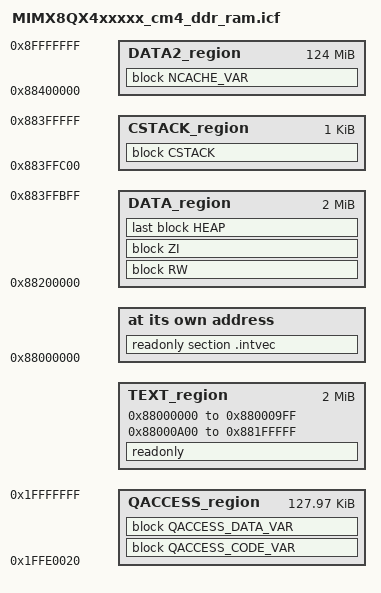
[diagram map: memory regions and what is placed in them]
/*
** ###################################################################
**     Processor:           MIMX8QX4AVLFZ
**     Compiler:            IAR ANSI C/C++ Compiler for ARM
**     Reference manual:    IMX8DQXPRM, Rev. E, 6/2019
**     Version:             rev. 3.0, 2018-08-22
**     Build:               b191127
**
**     Abstract:
**         Linker file for the IAR ANSI C/C++ Compiler for ARM
**
**     Copyright 2016 Freescale Semiconductor, Inc.
**     Copyright 2016-2019 NXP
**     All rights reserved.
**
**     SPDX-License-Identifier: BSD-3-Clause
**
**     http:                 www.nxp.com
**     mail:                 support@nxp.com
**
** ###################################################################
*/

/* DDR Memory region [0x88000000-0x8FFFFFFF] 128MB is allocated for CM4 */

define symbol m_interrupts_start       = 0x88000000;
define symbol m_interrupts_end         = 0x880009FF;

define symbol m_text_start             = 0x88000A00;
define symbol m_text_end               = 0x881FFFFF;

define symbol m_data_start             = 0x88200000;
define symbol m_data_end               = 0x883FFFFF;

define symbol m_data2_start            = 0x88400000;
define symbol m_data2_end              = 0x8FFFFFFF;

/* M4 always start up from TCM. The SCU will copy the first 32 bytes of the binary to TCM
if the start address is not TCM. The TCM region [0x1FFE0000-0x1FFE001F] is reserved for this purpose. */
define symbol m_tcml_start             = 0x1FFE0020;
define symbol m_tcml_end               = 0x1FFFFFFF;

define symbol m_tcmu_start             = 0x20000000;
define symbol m_tcmu_end               = 0x2001FFFF;

/* Sizes */
if (isdefinedsymbol(__stack_size__)) {
  define symbol __size_cstack__        = __stack_size__;
} else {
  define symbol __size_cstack__        = 0x0400;
}

if (isdefinedsymbol(__heap_size__)) {
  define symbol __size_heap__          = __heap_size__;
} else {
  define symbol __size_heap__          = 0x0400;
}

define exported symbol __CACHE_REGION_START   = m_interrupts_start;
define exported symbol __CACHE_REGION_SIZE    = m_data_end - m_interrupts_start + 1 ;

define memory mem with size = 4G;
define region TEXT_region = mem:[from m_interrupts_start to m_interrupts_end]
                          | mem:[from m_text_start to m_text_end];
define region DATA_region = mem:[from m_data_start to m_data_end-__size_cstack__];
define region CSTACK_region = mem:[from m_data_end-__size_cstack__+1 to m_data_end];
define region DATA2_region = mem:[from m_data2_start to m_data2_end];
define region QACCESS_region = mem:[from m_tcml_start to m_tcml_end];

define block CSTACK    with alignment = 8, size = __size_cstack__   { };
define block HEAP      with alignment = 8, size = __size_heap__     { };
define block RW        { readwrite };
define block ZI        { zi };
define block NCACHE_VAR    { section NonCacheable , section NonCacheable.init };
define block QACCESS_CODE_VAR   with alignment = 32 { section CodeQuickAccess };
define block QACCESS_DATA_VAR   with alignment = 32 { section DataQuickAccess };

initialize by copy { readwrite, section .textrw, section DataQuickAccess, section CodeQuickAccess };
do not initialize  { section .noinit };

place at address mem: m_interrupts_start    { readonly section .intvec };
place in TEXT_region                        { readonly };
place in DATA_region                        { block RW };
place in DATA_region                        { block ZI };
place in DATA_region                        { last block HEAP };
place in CSTACK_region                      { block CSTACK };
place in DATA2_region                       { block NCACHE_VAR };
place in QACCESS_region                     { block QACCESS_CODE_VAR };
place in QACCESS_region                     { block QACCESS_DATA_VAR };

